# K510 register map
Vendor: Canaan; File version: 1.0
Registers are 32-bit, read-write, reset 0x0 unless marked. A register's access mark holds for its fields unless they carry their own. Offsets are from the block's base; [hi:lo] are bit positions; {n}, {i} and the like mark numbered series; 'fields as' and 'values as' point back to an identical list.

## UART{n} — Universal Asynchronous Receivers/Transmitters
Base 0x96000000; array of 4, step 0x10000
0x00 UART_RBR ro — Receive Buffer Register
  [8:0] RBR
0x00 UART_DLL — Divisor Latch (Low) Register
  [7:0] DLL — Divisor Latch Low
0x00 UART_THR wo — Transmit Holding Register
  [8:0] THR
0x04 UART_DLH — Divisor Latch (High) Register
  [7:0] DLH — Divisor Latch High
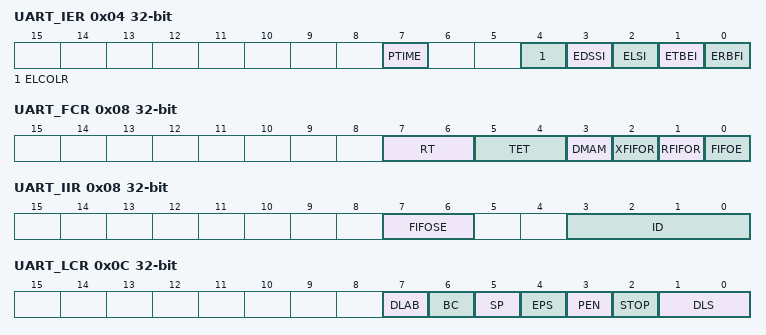
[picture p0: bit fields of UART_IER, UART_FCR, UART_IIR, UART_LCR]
0x04 UART_IER — Interrupt Enable Register
  [all] fields
    0=DISABLE; 1=ENABLE
  [7] PTIME — Programmable THRE Interrupt Mode Enable
  [4] ELCOLR ro
  [3] EDSSI — Enable Modem Status Interrupt
  [2] ELSI — Enable Receiver Line Status Interrupt
  [1] ETBEI — Enable Transmit Holding Register Empty Interrupt
  [0] ERBFI — Enable Receive Data Available Interrupt
0x08 UART_FCR wo — FIFO Control Register
  [7:6] RT — RCVR Trigger
    0=FIFO_CHAR_1 (1 character in FIFO); 1=FIFO_QUARTER_FULL (FIFO 1/4 full); 2=FIFO_HALF_FULL (FIFO 1/2 full); 3=FIFO_FULL_2 (FIFO 2 less than full)
  [5:4] TET — TX Empty Trigger
    0=FIFO_EMPTY; 1=FIFO_CHAR_2 (2 characters in FIFO); 2=FIFO_QUARTER_FULL (FIFO 1/4 full); 3=FIFO_HALF_FULL (FIFO 1/2 full)
  [3] DMAM — DMA Mode
    0=MODE0; 1=MODE1
  [2] XFIFOR write-clears — XMIT FIFO Reset
    1=RESET
  [1] RFIFOR write-clears — RCVR FIFO Reset
    1=RESET
  [0] FIFOE — FIFO Enable
    0=DISABLE; 1=ENABLE
0x08 UART_IIR ro — Interrupt Identification Register
  [7:6] FIFOSE — FIFOs Enabled
    0=DISABLE; 3=ENABLE
  [3:0] ID — Interrupt ID
    0=MODEM_STATUS; 1=NO_INTERRUPT_PENDING; 2=THR_EMPTY; 4=RECEIVED_DATA_AVAILABLE; 6=RECEIVER_LINE_STATUS; 7=BUSY_DETECT; 12=CHARACTER_TIMEOUT
0x0C UART_LCR — Line Control Register
  [7] DLAB — Divisor Latch Access Bit
    0=DISABLE; 1=ENABLE
  [6] BC — Break Control Bit
    0=DISABLE; 1=ENABLE
  [5] SP — Stick Parity
    0=DISABLE; 1=ENABLE
  [4] EPS — Even Parity Select
    0=ODD_PARITY (an odd parity is transmitted or checked); 1=EVEN_PARITY (an even parity is transmitted or checked)
  [3] PEN — Parity Enable
    0=DISABLE; 1=ENABLE
  [2] STOP — Number of stop bits
    0=STOP_1BIT (1 stop bit); 1=STOP_1_5BIT_OR_2BIT (1.5 stop bits or 2 stop bits)
  [1:0] DLS — Data Length Select
    {v}=CHAR_{v+5}BITS ({v+5} data bits per character) (v=0..3)
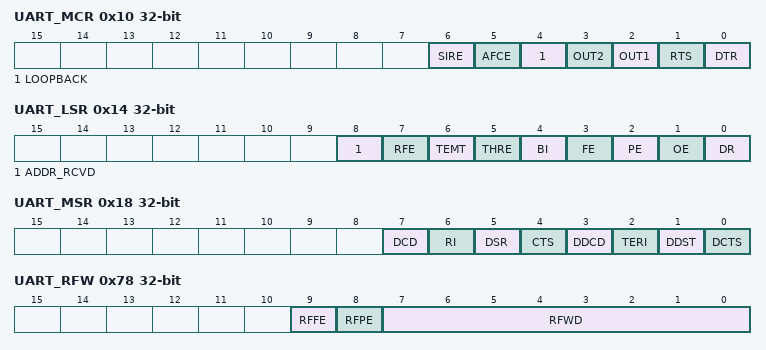
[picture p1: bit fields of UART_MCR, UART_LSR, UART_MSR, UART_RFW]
0x10 UART_MCR — Modem Control Register
  [6] SIRE — SIR Mode Enable
    0=DISABLE; 1=ENABLE
  [5] AFCE — Automatic Flow Control Enable
    0=DISABLE; 1=ENABLE
  [4] LOOPBACK — Loopback Bit
    0=DISABLE; 1=ENABLE
  [3] OUT2
    0=out2_n de-asserted; 1=out2_n asserted
  [2] OUT1
    0=out1_n de-asserted; 1=out1_n asserted
  [1] RTS — Request to Send
    0=INACTIVE (Request to Send rts_n de-asserted); 1=ACTIVE (Request to Send rts_n asserted)
  [0] DTR — Data Terminal Ready
    0=INACTIVE (Data Terminal Ready dtr_n de-asserted); 1=ACTIVE (Data Terminal Ready dtr_n asserted)
0x14 UART_LSR ro — Line Status Register
  [8] ADDR_RCVD — Address Received Bit
    0=DATA (the character is data); 1=ADDR (the character is an address)
  [7] RFE — Receive FIFO Error Bit
    0=NO_RX_FIFO_ERROR (no error in RX FIFO); 1=RX_FIFO_ERROR (error in RX FIFO)
  [6] TEMT — Transmitter Empty Bit
    0=NOT_EMPTY (transmitter is not empty); 1=EMPTY (transmitter is empty)
  [5] THRE — Transmit Holding Register Empty Bit
    values as TEMT
  [4] BI — Break Interrupt Bit
    0=NO_BREAK (no break detected); 1=BREAK (break detected)
  [3] FE — Framing Error Bit
    0=NO_FRAMING_ERROR; 1=FRAMING_ERROR
  [2] PE — Parity Error Bit
    0=NO_PARITY_ERROR; 1=PARITY_ERROR
  [1] OE — Overrun Error Bit
    0=NO_OVERRUN_ERROR; 1=OVERRUN_ERROR
  [0] DR — Data Ready Bit
    0=NOT_READY (data not ready); 1=READY (data ready)
0x18 UART_MSR ro — Modem Status Register
  [7] DCD — Data Carrier Detect
    0=DEASSERTED (dcd_n input is de-asserted); 1=ASSERTED (dcd_n input is asserted)
  [6] RI — Ring Indicator
    0=DEASSERTED (ri_n input is de-asserted); 1=ASSERTED (ri_n input is asserted)
  [5] DSR — Data Set Ready
    0=DEASSERTED (dsr_n input is de-asserted); 1=ASSERTED (dsr_n input is asserted)
  [4] CTS — Clear To Send
    0=DEASSERTED (cts_n input is de-asserted); 1=ASSERTED (cts_n input is asserted)
  [3] DDCD — Delta Data Carrier Detect
    0=NO_CHANGE (no change on dcd_n since last read of MSR); 1=CHANGE (change on dcd_n since last read of MSR)
  [2] TERI — Trailing Edge of Ring Indicator
    0=NO_CHANGE (no change on ri_n since last read of MSR); 1=CHANGE (change on ri_n since last read of MSR)
  [1] DDST — Delta Data Set Ready
    0=NO_CHANGE (no change on dsr_n since last read of MSR); 1=CHANGE (change on dsr_n since last read of MSR)
  [0] DCTS — Delta Clear To Send
    0=NO_CHANGE (no change on cts_n since last read of MSR); 1=CHANGE (change on cts_n since last read of MSR)
0x1C UART_SCR — Scratch Pad Register
  [7:0] SCR
0x20 UART_LPDLL — Low Power Divisor Latch Low Register
  [7:0] LPDLL
0x24 UART_LPDLH — Low Power Divisor Latch High Register
  [7:0] LPDLH
{0x30+4i} UART_SRBR{i} (i=0..15) ro — Shadow Receive Buffer Register
  [8:0] SRBR
{0x30+4i} UART_STHR{i} (i=0..15) wo — Shadow Transmit Holding Register
  [8:0] STHR
0x70 UART_FAR ro — FIFO Access Register
  [0] FAR — FIFO Access
    0=DISABLED (FIFO access mode disabled); 1=ENABLED (FIFO access mode enabled)
0x74 UART_TFR ro — Transmit FIFO Read
  [7:0] TFR
0x78 UART_RFW wo — Receive FIFO control
  [9] RFFE — Receive FIFO Framing Error
    0=DISABLED (Receive FIFO framing error disabled); 1=ENABLED (Receive FIFO framing error enabled)
  [8] RFPE — Receive FIFO Parity Error
    0=DISABLED (Receive FIFO parity error disabled); 1=ENABLED (Receive FIFO parity error enabled)
  [7:0] RFWD — Receive FIFO Write Data
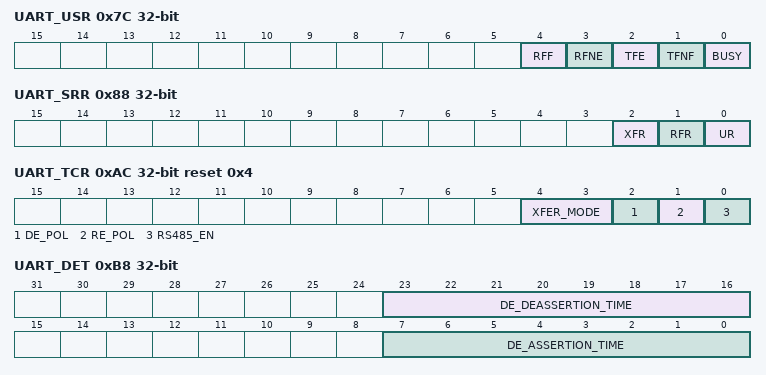
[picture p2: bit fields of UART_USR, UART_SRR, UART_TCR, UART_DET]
0x7C UART_USR ro — UART Status Register
  [4] RFF — Receive FIFO Full
    0=NOT_FULL (Receive FIFO not full); 1=FULL (Receive FIFO full)
  [3] RFNE — Receive FIFO Not Empty
    0=EMPTY (Receive FIFO empty); 1=NOT_EMPTY (Receive FIFO not empty)
  [2] TFE — Transmit FIFO Empty
    0=NOT_EMPTY (Transmit FIFO not empty); 1=EMPTY (Transmit FIFO empty)
  [1] TFNF — Transmit FIFO Not Full
    0=FULL (Transmit FIFO full); 1=NOT_FULL (Transmit FIFO not full)
  [0] BUSY — UART Busy
    0=IDLE (uart is idle or inactive); 1=BUSY (uart is busy)
0x80 UART_TFL ro — Transmit FIFO Level
  [5:0] TFL
0x84 UART_RFL ro — Receive FIFO Level
  [5:0] RFL
0x88 UART_SRR wo
  [2] XFR — XMIT FIFO Reset
  [1] RFR — RCVR FIFO Reset
  [0] UR — UART Reset
    1=RESET (Reset UART)
0x8C UART_SRTS
  [0] SRTS — Shadow Request to Send
    0=DEASSERTED; 1=ASSERTED
0x90 UART_SBCR
  [0] SBCR — Shadow Break Control
    0=NO_BREAK (No spacing on serial output); 1=BREAK (Serial output forced to the spacing)
0x94 UART_SDMAM — Shadow DMA Mode
  [0] SDMAM
    0=MODE0; 1=MODE1
0x98 UART_SFE — Shadow FIFO Enable
  [0] SFE
    0=DISABLE; 1=ENABLE
0x9C UART_SRT — Shadow Receive Trigger
  [1:0] SRT — Shadow RCVR Trigger
    values as UART_FCR.RT
0xA0 UART_STET — Shadow Transmit Empty Trigger
  [1:0] STET — Shadow TX Empty Trigger
    values as UART_FCR.TET
0xA4 UART_HTX — Halt Tx
  [0] HTX
    0=DISABLE (Halt Transmission disable); 1=ENABLE (Halt Transmission enable)
0xA8 UART_DMASA wo — DMA Software Acknowledge Register
  [0] DMASA
    1=SOFT_ACK (DMA software acknowledge)
0xAC UART_TCR reset 0x4 (reset mask 0xF) — enable or disable RS485 mode
  [4:3] XFER_MODE — Transfer Mode
    0=MODE0; 1=MODE1; 2=MODE2
  [2] DE_POL — Driver Enable Polarity
    0=ACTIVE_LOW (Driver Enable active low); 1=ACTIVE_HIGH (Driver Enable active high)
  [1] RE_POL — Receiver Enable Polarity
    0=ACTIVE_LOW (Receiver Enable active low); 1=ACTIVE_HIGH (Receiver Enable active high)
  [0] RS485_EN — RS485 Transfer Enable
    0=DISABLE (RS485 transfer disable); 1=ENABLE (RS485 transfer enable)
0xB0 UART_DE_EN — The Driver Output Enable Register
  [0] DE_EN — DE Enable
    0=DISABLE (De-assert 'de' signal); 1=ENABLE (Assert 'de' signal)
0xB4 UART_RE_EN — The Receiver Output Enable Register
  [0] RE_EN — RE Enable
    0=DISABLE (De-assert 're' signal); 1=ENABLE (Assert 're' signal)
0xB8 UART_DET — The Driver Output Enable Timing Register
  [23:16] DE_DEASSERTION_TIME, [7:0] DE_ASSERTION_TIME
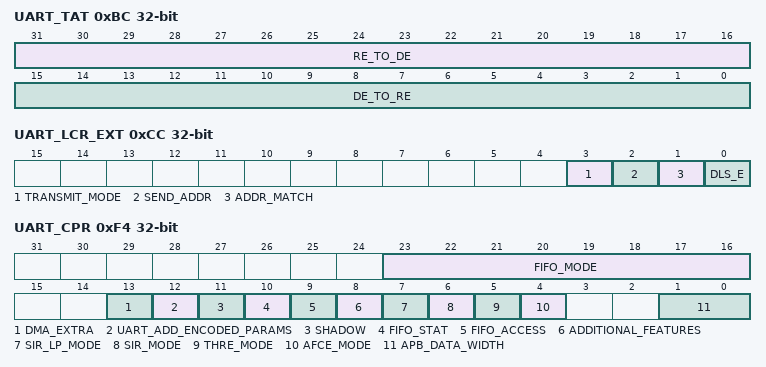
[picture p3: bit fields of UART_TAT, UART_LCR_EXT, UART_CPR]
0xBC UART_TAT — The Turn Around Timing Register
  [31:16] RE_TO_DE — Receiver Enable to Driver Enable Turn Around Time
  [15:0] DE_TO_RE — Driver Enable to Receiver Enable Turn Around Time
0xC0 UART_DLF — Fractional Baud rate Divisor
  [3:0] DLF — Fractional part of divisor
0xC4 UART_RAR — Receive Address Register
  [7:0] RAR — Receive Address
0xC8 UART_TAR — Transmit Address Register
  [7:0] TAR — Transmit Address
0xCC UART_LCR_EXT — Line Control Register Extended
  [3] TRANSMIT_MODE — Transmit Mode Control
    0=MODE0; 1=MODE1
  [2] SEND_ADDR — Send Address Control
  [1] ADDR_MATCH — Address Match Mode
    0=NORMAL_MODE; 1=ADDRESS_MATCH_MODE
  [0] DLS_E — Extension for DLS
0xF4 UART_CPR ro — Component Parameter Register
  [23:16] FIFO_MODE
    0=FIFO mode is 0; 1=FIFO mode is 16; 2=FIFO mode is 32; 4=FIFO mode is 64; 8=FIFO mode is 128; 16=FIFO mode is 256; 32=FIFO mode is 512; 64=FIFO mode is 1024; 128=FIFO mode is 2048
  [13] DMA_EXTRA
    0=DISABLED (DMA_EXTRA disabled); 1=ENABLED (DMA_EXTRA enabled)
  [12] UART_ADD_ENCODED_PARAMS
    0=DISABLED (UART_ADD_ENCODED_PARAMS disabled); 1=ENABLED (UART_ADD_ENCODED_PARAMS enabled)
  [11] SHADOW
    0=DISABLED (SHADOW disabled); 1=ENABLED (SHADOW enabled)
  [10] FIFO_STAT
    0=DISABLED (FIFO_STAT disabled); 1=ENABLED (FIFO_STAT enabled)
  [9] FIFO_ACCESS
    0=DISABLED (FIFO_ACCESS disabled); 1=ENABLED (FIFO_ACCESS enabled)
  [8] ADDITIONAL_FEATURES
    0=DISABLED (ADDITIONAL_FEATURES disabled); 1=ENABLED (ADDITIONAL_FEATURES enabled)
  [7] SIR_LP_MODE
    0=DISABLED (SIR_LP_MODE disabled); 1=ENABLED (SIR_LP_MODE enabled)
  [6] SIR_MODE
    0=DISABLED (SIR_MODE disabled); 1=ENABLED (SIR_MODE enabled)
  [5] THRE_MODE
    0=DISABLED (THRE_MODE disabled); 1=ENABLED (THRE_MODE enabled)
  [4] AFCE_MODE
    0=DISABLED (AFCE_MODE disabled); 1=ENABLED (AFCE_MODE enabled)
  [1:0] APB_DATA_WIDTH
    0=APB_8BITS (APB data width is 8 bits); 1=APB_16BITS (APB data width is 16 bits); 2=APB_32BITS (APB data width is 32 bits)
0xF8 UART_UCV ro
  [31:0] UART_COMPONENT_VERSION
0xFC UART_CTR ro
  [31:0] PERIPHERAL_ID
